# STM32MP13xx register map
File version: 1.7
CPU: CA7 r0p0, little endian, MPU, FPU, 4 interrupt priority bits
Registers are 32-bit, read-write, reset 0x0 unless marked. A register's access mark holds for its fields unless they carry their own. Offsets are from the block's base; [hi:lo] are bit positions; {n}, {i} and the like mark numbered series.

## DLYBSD1 — DLYB
Base 0x58006000
Same registers: DLYBQS 0x58004000, DLYBSD2 0x58008000
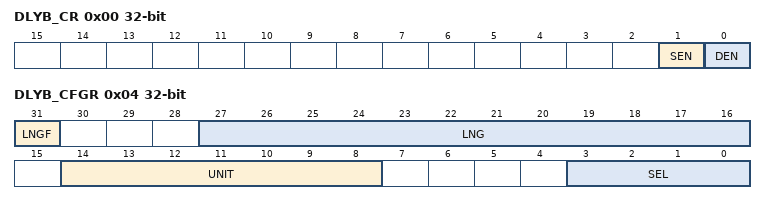
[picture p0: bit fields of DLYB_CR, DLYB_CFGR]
0x00 DLYB_CR — DLYB control register
  [1] SEN — Sampler length enable bit
    0=Sampler length and register access to UNIT[6:0] and SEL[3:0] disabled, output clock enabled; 1=Sampler length and register access to UNIT[6:0] and SEL[3:0] enabled, output clock disabled
  [0] DEN — Delay block enable bit
    0=DLYB disabled; 1=DLYB enabled
0x04 DLYB_CFGR access per field — DLYB configuration register
  [31] LNGF ro — Length valid flag This flag indicates when the delay line length value contained in LNG[11:0] is valid after UNIT[6:0] bits changed.
    0=Length value in LNG is not valid; 1=Length value in LNG is valid
  [27:16] LNG ro — Delay line length value These bits reflect the 12 unit delay values sampled at the rising edge of the input clock. The value is only valid when LNGF = 1.
  [14:8] UNIT rw — Delay of a unit delay cell. These bits can only be written when SEN = 1. Unit delay = initial delay + UNIT[6:0] x delay step
  [3:0] SEL rw — Phase for the output clock. These bits can only be written when SEN = 1. Output clock phase = input clock + SEL[3:0] x unit delay

## DMAMUX1
Base 0x48002000
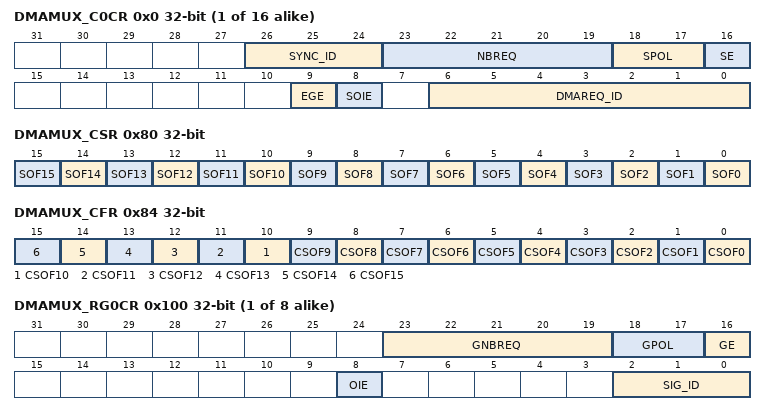
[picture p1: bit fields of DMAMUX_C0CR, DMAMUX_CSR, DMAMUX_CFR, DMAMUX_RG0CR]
{0x0+4i} DMAMUX_C{i}CR (i=0..15) — DMAMUX request line multiplexer channel {i} configuration register
  [26:24] SYNC_ID, [23:19] NBREQ, [18:17] SPOL, [16] SE, [9] EGE, [8] SOIE, [6:0] DMAREQ_ID
0x80 DMAMUX_CSR ro — DMAMUX request line multiplexer interrupt channel status register
  [n] SOF{n} (n=0..15)
0x84 DMAMUX_CFR wo — DMAMUX request line multiplexer interrupt clear flag register
  [n] CSOF{n} (n=0..15)
{0x100+4i} DMAMUX_RG{i}CR (i=0..7) — DMAMUX request generator channel {i} configuration register
  [23:19] GNBREQ, [18:17] GPOL, [16] GE, [8] OIE, [2:0] SIG_ID
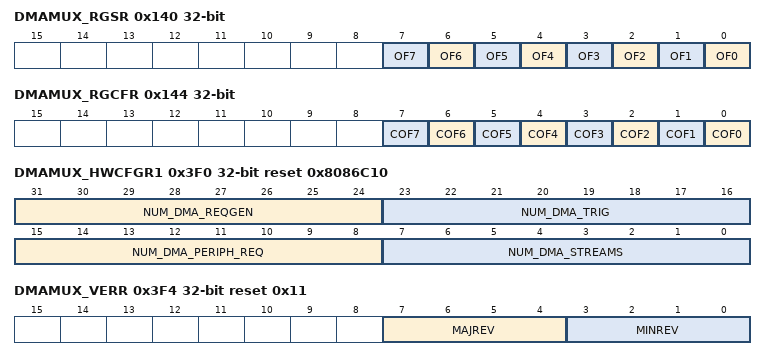
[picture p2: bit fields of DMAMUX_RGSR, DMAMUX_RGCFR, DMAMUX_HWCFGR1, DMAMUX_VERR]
0x140 DMAMUX_RGSR ro — DMAMUX request generator interrupt status register
  [n] OF{n} (n=0..7)
0x144 DMAMUX_RGCFR wo — DMAMUX request generator interrupt clear flag register
  [n] COF{n} (n=0..7)
0x3EC DMAMUX_HWCFGR2 ro reset 0x8 — DMAMUX hardware configuration 2 register
  [7:0] NUM_DMA_EXT_REQ
0x3F0 DMAMUX_HWCFGR1 ro reset 0x8086C10 — DMAMUX hardware configuration 1 register
  [31:24] NUM_DMA_REQGEN, [23:16] NUM_DMA_TRIG, [15:8] NUM_DMA_PERIPH_REQ, [7:0] NUM_DMA_STREAMS
0x3F4 DMAMUX_VERR ro reset 0x11 — This register identifies the IP version.
  [7:4] MAJREV, [3:0] MINREV
0x3F8 DMAMUX_IPIDR ro reset 0x100011 — This register identifies the IP.
  [31:0] ID
0x3FC DMAMUX_SIDR ro reset 0xA3C5DD01 — DMAMUX size identification register
  [31:0] SID

## DMAMUX2
Base 0x48006000
Registers as DMAMUX1, without DMAMUX_C{n}CR (n=8..15); these are added or differ:
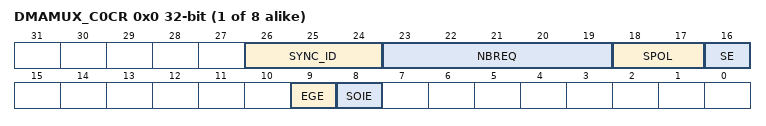
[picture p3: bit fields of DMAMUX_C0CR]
{0x0+4i} DMAMUX_C{i}CR (i=0..7) — DMAMUX request line multiplexer channel {i} configuration register
  [26:24] SYNC_ID, [23:19] NBREQ, [18:17] SPOL, [16] SE, [9] EGE, [8] SOIE

## DTS — DTS register block
Base 0x50028000
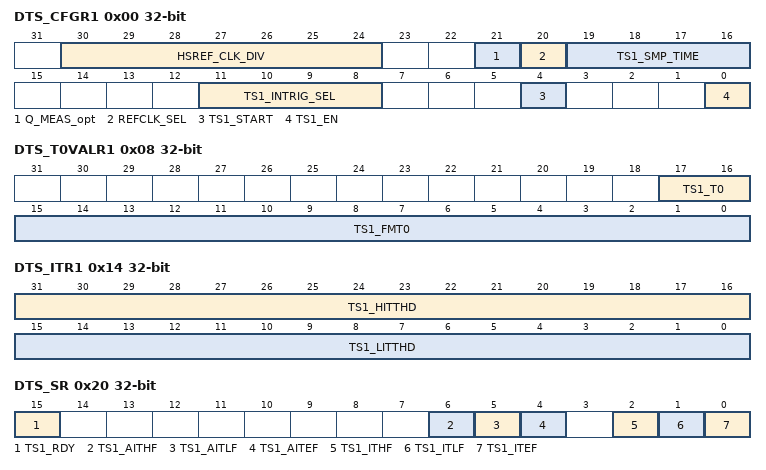
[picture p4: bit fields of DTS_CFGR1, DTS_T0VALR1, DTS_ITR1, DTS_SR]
0x00 DTS_CFGR1 — DTS_CFGR1 is the configuration register for temperature sensor 1.
  [30:24] HSREF_CLK_DIV, [21] Q_MEAS_opt, [20] REFCLK_SEL, [19:16] TS1_SMP_TIME, [11:8] TS1_INTRIG_SEL, [4] TS1_START, [0] TS1_EN
0x08 DTS_T0VALR1 ro — DTS_T0VALR1 contains the value of the factory calibration temperature (T0) for temperature sensor 1. The system reset value is factory trimmed.
  [17:16] TS1_T0, [15:0] TS1_FMT0
0x10 DTS_RAMPVALR ro — The DTS_RAMPVALR is the ramp coefficient for the temperature sensor. The system reset value is factory trimmed.
  [15:0] TS1_RAMP_COEFF
0x14 DTS_ITR1 — DTS_ITR1 contains the threshold values for sensor 1.
  [31:16] TS1_HITTHD, [15:0] TS1_LITTHD
0x1C DTS_DR — The DTS_DR contains the number of REF_CLK cycles used to compute the FM(T) frequency.
  [15:0] TS1_MFREQ
0x20 DTS_SR ro — Temperature sensor status register
  [15] TS1_RDY, [6] TS1_AITHF, [5] TS1_AITLF, [4] TS1_AITEF, [2] TS1_ITHF, [1] TS1_ITLF, [0] TS1_ITEF
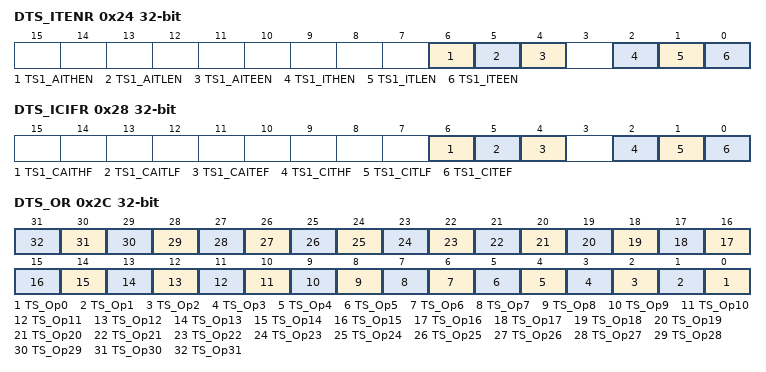
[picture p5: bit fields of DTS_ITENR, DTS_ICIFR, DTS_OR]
0x24 DTS_ITENR — Temperature sensor interrupt enable register
  [6] TS1_AITHEN, [5] TS1_AITLEN, [4] TS1_AITEEN, [2] TS1_ITHEN, [1] TS1_ITLEN, [0] TS1_ITEEN
0x28 DTS_ICIFR — DTS_ICIFR is the control register for the interrupt flags.
  [6] TS1_CAITHF, [5] TS1_CAITLF, [4] TS1_CAITEF, [2] TS1_CITHF, [1] TS1_CITLF, [0] TS1_CITEF
0x2C DTS_OR — The DTS_OR contains general-purpose option bits.
  [n] TS_Op{n} (n=0..31)
